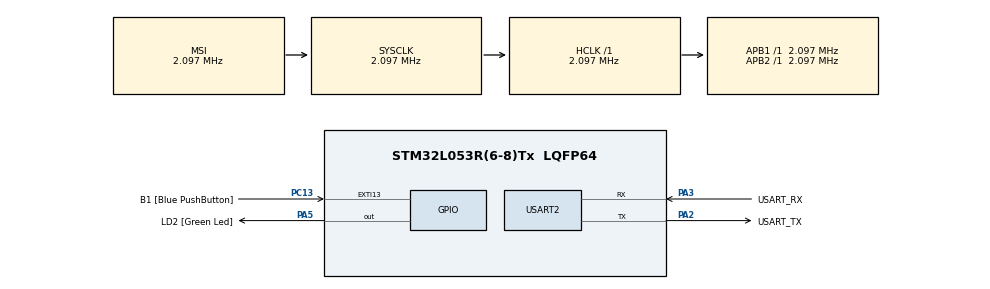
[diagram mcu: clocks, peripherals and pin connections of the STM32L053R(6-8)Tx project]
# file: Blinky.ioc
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Mcu.Family=STM32L0
RCC.MSI_VALUE=2097000
PC15-OSC32_OUT.Mode=LSE-External-Oscillator
PH0-OSC_IN.Signal=RCC_OSC_IN
PC13.Signal=GPXTI13
PA14.GPIO_Label=TCK
PC13.GPIO_Label=B1 [Blue PushButton]
PC14-OSC32_IN.Signal=RCC_OSC32_IN
ProjectManager.StackSize=0x400
PA3.Mode=Asynchronous
PA13.Signal=SYS_SWDIO
RCC.HSI16_VALUE=16000000
ProjectManager.TargetToolchain=EWARM V8.32
RCC.APB2TimFreq_Value=2097000
PC15-OSC32_OUT.Signal=RCC_OSC32_OUT
RCC.AHBFreq_Value=2097000
PH0-OSC_IN.Mode=HSE-External-Clock-Source
PA5.Signal=GPIO_Output
RCC.HSE_VALUE=8000000
board=NUCLEO-L053R8
USART2.VirtualMode-Asynchronous=VM_ASYNC
RCC.VCOOutputFreq_Value=48000000
RCC.APB2Freq_Value=2097000
PC14-OSC32_IN.Mode=LSE-External-Oscillator
PA14.Mode=Serial_Wire
PH1-OSC_OUT.Signal=RCC_OSC_OUT
PA13.Mode=Serial_Wire
Mcu.Name=STM32L053R(6-8)Tx
PA2.Signal=USART2_TX
PA13.GPIO_Label=TMS
RCC.SYSCLKFreq_VALUE=2097000
Mcu.Package=LQFP64
PA5.GPIO_Label=LD2 [Green Led]
PC13.GPIO_ModeDefaultEXTI=GPIO_MODE_IT_FALLING
PA2.GPIO_Label=USART_TX
PA14.Signal=SYS_SWCLK
ProjectManager.HeapSize=0x200
RCC.HSI_VALUE=16000000
RCC.APB1TimFreq_Value=2097000
PA2.Mode=Asynchronous
RCC.APB1Freq_Value=2097000
RCC.HSI48_VALUE=48000000
PA3.GPIO_Label=USART_RX
PA3.Signal=USART2_RX

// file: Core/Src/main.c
/* USER CODE BEGIN Header */
/**
  ******************************************************************************
  * @file           : main.c
  * @brief          : Main program body
  ******************************************************************************
  * @attention
  *
  * <h2><center>&copy; Copyright (c) 2020 STMicroelectronics.
  * All rights reserved.</center></h2>
  *
  * This software component is licensed by ST under BSD 3-Clause license,
  * the "License"; You may not use this file except in compliance with the
  * License. You may obtain a copy of the License at:
  *                        opensource.org/licenses/BSD-3-Clause
  *
  ******************************************************************************
  */
/* USER CODE END Header */
#include "main.h"

/* USER CODE BEGIN PD */
#define myled GPIO_PIN_5
/* USER CODE END PD */

UART_HandleTypeDef huart2;

void SystemClock_Config(void);
static void MX_GPIO_Init(void);
static void MX_USART2_UART_Init(void);

int main(void)
{

  /* MCU Configuration--------------------------------------------------------*/

  /* Reset of all peripherals, Initializes the Flash interface and the Systick. */
  HAL_Init();

  /* Configure the system clock */
  SystemClock_Config();

  /* Initialize all configured peripherals */
  MX_GPIO_Init();
  MX_USART2_UART_Init();

  /* Infinite loop */
  while (1)
  {
    HAL_GPIO_WritePin(GPIOA,myled,GPIO_PIN_SET);
    HAL_Delay(200);
    HAL_GPIO_WritePin(GPIOA,myled,GPIO_PIN_RESET);
    HAL_Delay(100);
    HAL_GPIO_WritePin(GPIOA,myled,GPIO_PIN_SET);
    HAL_Delay(200);
    HAL_GPIO_WritePin(GPIOA,myled,GPIO_PIN_RESET);
    HAL_Delay(100);
    HAL_Delay(400);

  }
}

void SystemClock_Config(void)
{
  RCC_OscInitTypeDef RCC_OscInitStruct = {0};
  RCC_ClkInitTypeDef RCC_ClkInitStruct = {0};
  RCC_PeriphCLKInitTypeDef PeriphClkInit = {0};

  /** Configure the main internal regulator output voltage
  */
  __HAL_PWR_VOLTAGESCALING_CONFIG(PWR_REGULATOR_VOLTAGE_SCALE1);
  /** Initializes the RCC Oscillators according to the specified parameters
  * in the RCC_OscInitTypeDef structure.
  */
  RCC_OscInitStruct.OscillatorType = RCC_OSCILLATORTYPE_MSI;
  RCC_OscInitStruct.MSIState = RCC_MSI_ON;
  RCC_OscInitStruct.MSICalibrationValue = 0;
  RCC_OscInitStruct.MSIClockRange = RCC_MSIRANGE_5;
  RCC_OscInitStruct.PLL.PLLState = RCC_PLL_NONE;
  if (HAL_RCC_OscConfig(&RCC_OscInitStruct) != HAL_OK)
  {
    Error_Handler();
  }
  /** Initializes the CPU, AHB and APB buses clocks
  */
  RCC_ClkInitStruct.ClockType = RCC_CLOCKTYPE_HCLK|RCC_CLOCKTYPE_SYSCLK
                              |RCC_CLOCKTYPE_PCLK1|RCC_CLOCKTYPE_PCLK2;
  RCC_ClkInitStruct.SYSCLKSource = RCC_SYSCLKSOURCE_MSI;
  RCC_ClkInitStruct.AHBCLKDivider = RCC_SYSCLK_DIV1;
  RCC_ClkInitStruct.APB1CLKDivider = RCC_HCLK_DIV1;
  RCC_ClkInitStruct.APB2CLKDivider = RCC_HCLK_DIV1;

  if (HAL_RCC_ClockConfig(&RCC_ClkInitStruct, FLASH_LATENCY_0) != HAL_OK)
  {
    Error_Handler();
  }
  PeriphClkInit.PeriphClockSelection = RCC_PERIPHCLK_USART2;
  PeriphClkInit.Usart2ClockSelection = RCC_USART2CLKSOURCE_PCLK1;
  if (HAL_RCCEx_PeriphCLKConfig(&PeriphClkInit) != HAL_OK)
  {
    Error_Handler();
  }
}

static void MX_USART2_UART_Init(void)
{

  huart2.Instance = USART2;
  huart2.Init.BaudRate = 115200;
  huart2.Init.WordLength = UART_WORDLENGTH_8B;
  huart2.Init.StopBits = UART_STOPBITS_1;
  huart2.Init.Parity = UART_PARITY_NONE;
  huart2.Init.Mode = UART_MODE_TX_RX;
  huart2.Init.HwFlowCtl = UART_HWCONTROL_NONE;
  huart2.Init.OverSampling = UART_OVERSAMPLING_16;
  huart2.Init.OneBitSampling = UART_ONE_BIT_SAMPLE_DISABLE;
  huart2.AdvancedInit.AdvFeatureInit = UART_ADVFEATURE_NO_INIT;
  if (HAL_UART_Init(&huart2) != HAL_OK)
  {
    Error_Handler();
  }

}

static void MX_GPIO_Init(void)
{
  GPIO_InitTypeDef GPIO_InitStruct = {0};

  /* GPIO Ports Clock Enable */
  __HAL_RCC_GPIOC_CLK_ENABLE();
  __HAL_RCC_GPIOH_CLK_ENABLE();
  __HAL_RCC_GPIOA_CLK_ENABLE();
  __HAL_RCC_GPIOB_CLK_ENABLE();
  __HAL_RCC_GPIOD_CLK_ENABLE();

  /*Configure GPIO pin Output Level */
  HAL_GPIO_WritePin(LD2_GPIO_Port, LD2_Pin, GPIO_PIN_RESET);

  /*Configure GPIO pin : B1_Pin */
  GPIO_InitStruct.Pin = B1_Pin;
  GPIO_InitStruct.Mode = GPIO_MODE_IT_FALLING;
  GPIO_InitStruct.Pull = GPIO_NOPULL;
  HAL_GPIO_Init(B1_GPIO_Port, &GPIO_InitStruct);

  /*Configure GPIO pins : PC0 PC1 PC2 PC3
                           PC4 PC5 PC6 PC7
                           PC8 PC9 PC10 PC11
                           PC12 */
  GPIO_InitStruct.Pin = GPIO_PIN_0|GPIO_PIN_1|GPIO_PIN_2|GPIO_PIN_3
                          |GPIO_PIN_4|GPIO_PIN_5|GPIO_PIN_6|GPIO_PIN_7
                          |GPIO_PIN_8|GPIO_PIN_9|GPIO_PIN_10|GPIO_PIN_11
                          |GPIO_PIN_12;
  GPIO_InitStruct.Mode = GPIO_MODE_ANALOG;
  GPIO_InitStruct.Pull = GPIO_NOPULL;
  HAL_GPIO_Init(GPIOC, &GPIO_InitStruct);

  /*Configure GPIO pins : PA0 PA1 PA4 PA6
                           PA7 PA8 PA9 PA10
                           PA11 PA12 PA15 */
  GPIO_InitStruct.Pin = GPIO_PIN_0|GPIO_PIN_1|GPIO_PIN_4|GPIO_PIN_6
                          |GPIO_PIN_7|GPIO_PIN_8|GPIO_PIN_9|GPIO_PIN_10
                          |GPIO_PIN_11|GPIO_PIN_12|GPIO_PIN_15;
  GPIO_InitStruct.Mode = GPIO_MODE_ANALOG;
  GPIO_InitStruct.Pull = GPIO_NOPULL;
  HAL_GPIO_Init(GPIOA, &GPIO_InitStruct);

  /*Configure GPIO pin : LD2_Pin */
  GPIO_InitStruct.Pin = LD2_Pin;
  GPIO_InitStruct.Mode = GPIO_MODE_OUTPUT_PP;
  GPIO_InitStruct.Pull = GPIO_NOPULL;
  GPIO_InitStruct.Speed = GPIO_SPEED_FREQ_LOW;
  HAL_GPIO_Init(LD2_GPIO_Port, &GPIO_InitStruct);

  /*Configure GPIO pins : PB0 PB1 PB2 PB10
                           PB11 PB12 PB13 PB14
                           PB15 PB3 PB4 PB5
                           PB6 PB7 PB8 PB9 */
  GPIO_InitStruct.Pin = GPIO_PIN_0|GPIO_PIN_1|GPIO_PIN_2|GPIO_PIN_10
                          |GPIO_PIN_11|GPIO_PIN_12|GPIO_PIN_13|GPIO_PIN_14
                          |GPIO_PIN_15|GPIO_PIN_3|GPIO_PIN_4|GPIO_PIN_5
                          |GPIO_PIN_6|GPIO_PIN_7|GPIO_PIN_8|GPIO_PIN_9;
  GPIO_InitStruct.Mode = GPIO_MODE_ANALOG;
  GPIO_InitStruct.Pull = GPIO_NOPULL;
  HAL_GPIO_Init(GPIOB, &GPIO_InitStruct);

  /*Configure GPIO pin : PD2 */
  GPIO_InitStruct.Pin = GPIO_PIN_2;
  GPIO_InitStruct.Mode = GPIO_MODE_ANALOG;
  GPIO_InitStruct.Pull = GPIO_NOPULL;
  HAL_GPIO_Init(GPIOD, &GPIO_InitStruct);

}

void Error_Handler(void)
{
}

/************************ (C) COPYRIGHT STMicroelectronics *****END OF FILE****/
